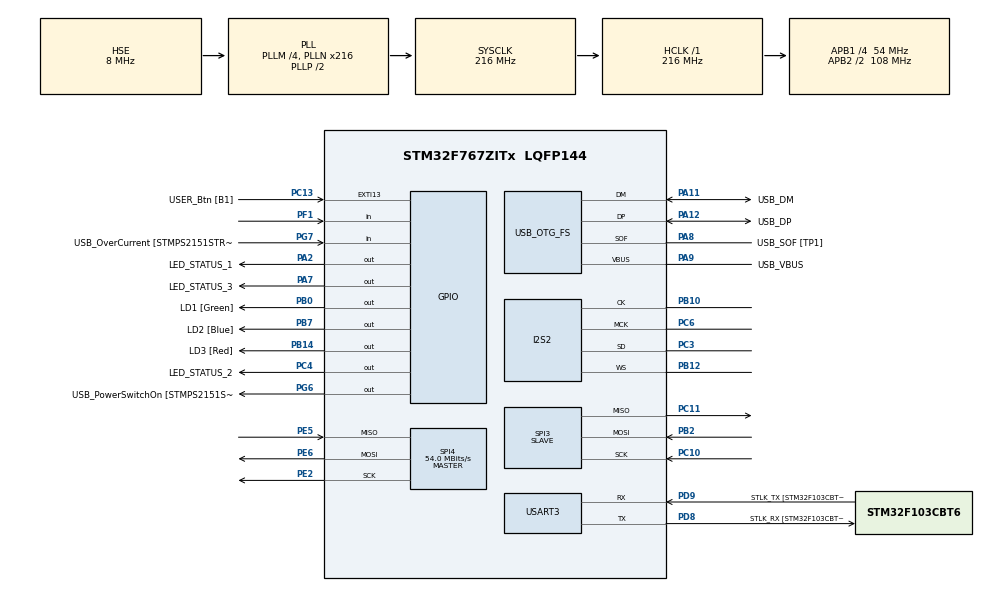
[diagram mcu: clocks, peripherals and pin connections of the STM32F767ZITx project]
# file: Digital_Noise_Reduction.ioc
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Dma.Request0=SPI2_RX
Dma.SPI2_RX.0.Direction=DMA_PERIPH_TO_MEMORY
Dma.SPI2_RX.0.FIFOMode=DMA_FIFOMODE_DISABLE
Dma.SPI2_RX.0.Instance=DMA1_Stream1
Dma.SPI2_RX.0.MemDataAlignment=DMA_MDATAALIGN_HALFWORD
Dma.SPI2_RX.0.MemInc=DMA_MINC_ENABLE
Dma.SPI2_RX.0.Mode=DMA_CIRCULAR
Dma.SPI2_RX.0.PeriphDataAlignment=DMA_PDATAALIGN_HALFWORD
Dma.SPI2_RX.0.PeriphInc=DMA_PINC_DISABLE
Dma.SPI2_RX.0.Priority=DMA_PRIORITY_HIGH
I2S2.AudioFreq=I2S_AUDIOFREQ_22K
I2S2.DataFormat=I2S_DATAFORMAT_24B
I2S2.ErrorAudioFreq=-0.06 %
I2S2.FullDuplexMode=I2S_FULLDUPLEXMODE_DISABLE
I2S2.Instance=SPI$Index
I2S2.Mode=I2S_MODE_MASTER_RX
I2S2.RealAudioFreq=21.986 KHz
I2S2.VirtualMode=I2S_MODE_MASTER
Mcu.Family=STM32F7
Mcu.Name=STM32F767ZITx
Mcu.Package=LQFP144
NVIC.DMA1_Stream1_IRQn=true\:0\:0\:false\:false\:true\:false\:true\:true
NVIC.OTG_FS_IRQn=true\:0\:0\:false\:false\:true\:false\:true\:true
NVIC.PriorityGroup=NVIC_PRIORITYGROUP_4
PA1.GPIO_Label=RMII_REF_CLK [LAN8742A-CZ-TR_REFCLK0]
PA1.Signal=ETH_REF_CLK
PA10.GPIO_Label=USB_ID
PA10.Signal=USB_OTG_FS_ID
PA11.GPIO_Label=USB_DM
PA11.Mode=Device_Only
PA11.Signal=USB_OTG_FS_DM
PA12.GPIO_Label=USB_DP
PA12.Mode=Device_Only
PA12.Signal=USB_OTG_FS_DP
PA13.GPIO_Label=TMS
PA13.Mode=Serial_Wire
PA13.Signal=SYS_JTMS-SWDIO
PA14.GPIO_Label=TCK
PA14.Mode=Serial_Wire
PA14.Signal=SYS_JTCK-SWCLK
PA2.GPIO_Label=LED_STATUS_1
PA2.Signal=GPIO_Output
PA7.GPIO_Label=LED_STATUS_3
PA7.Signal=GPIO_Output
PA8.GPIO_Label=USB_SOF [TP1]
PA8.Mode=Activate_SOF_FS
PA8.Signal=USB_OTG_FS_SOF
PA9.GPIO_Label=USB_VBUS
PA9.Mode=Activate_VBUS
PA9.Signal=USB_OTG_FS_VBUS
PB0.GPIO_Label=LD1 [Green]
PB0.Signal=GPIO_Output
PB10.Mode=Half_Duplex_Master
PB10.Signal=I2S2_CK
PB12.Mode=Half_Duplex_Master
PB12.Signal=I2S2_WS
PB13.GPIO_Label=RMII_TXD1 [LAN8742A-CZ-TR_TXD1]
PB13.Signal=ETH_TXD1
PB14.GPIO_Label=LD3 [Red]
PB14.Signal=GPIO_Output
PB2.Mode=Full_Duplex_Slave
PB2.Signal=SPI3_MOSI
PB3.GPIO_Label=SWO
PB3.Signal=SYS_JTDO-SWO
PB7.GPIO_Label=LD2 [Blue]
PB7.Signal=GPIO_Output
PC1.GPIO_Label=RMII_MDC [LAN8742A-CZ-TR_MDC]
PC1.Signal=ETH_MDC
PC10.Mode=Full_Duplex_Slave
PC10.Signal=SPI3_SCK
PC11.Mode=Full_Duplex_Slave
PC11.Signal=SPI3_MISO
PC13.GPIO_Label=USER_Btn [B1]
PC13.Signal=GPXTI13
PC14/OSC32_IN.Mode=LSE-External-Oscillator
PC14/OSC32_IN.Signal=RCC_OSC32_IN
PC15/OSC32_OUT.Mode=LSE-External-Oscillator
PC15/OSC32_OUT.Signal=RCC_OSC32_OUT
PC3.Mode=Half_Duplex_Master
PC3.Signal=I2S2_SD
PC4.GPIO_Label=LED_STATUS_2
PC4.Signal=GPIO_Output
PC5.GPIO_Label=RMII_RXD1 [LAN8742A-CZ-TR_RXD1]
PC5.Signal=ETH_RXD1
PC6.Mode=Master_Clock_Activated
PC6.Signal=I2S2_MCK
PD8.GPIO_Label=STLK_RX [STM32F103CBT6_PA3]
PD8.Mode=Asynchronous
PD8.Signal=USART3_TX
PD9.GPIO_Label=STLK_TX [STM32F103CBT6_PA2]
PD9.Mode=Asynchronous
PD9.Signal=USART3_RX
PE2.Mode=Full_Duplex_Master
PE2.Signal=SPI4_SCK
PE5.Mode=Full_Duplex_Master
PE5.Signal=SPI4_MISO
PE6.Mode=Full_Duplex_Master
PE6.Signal=SPI4_MOSI
PF1.Signal=GPIO_Input
PG11.GPIO_Label=RMII_TX_EN [LAN8742A-CZ-TR_TXEN]
PG11.Signal=ETH_TX_EN
PG13.GPIO_Label=RMII_TXD0 [LAN8742A-CZ-TR_TXD0]
PG13.Signal=ETH_TXD0
PG6.GPIO_Label=USB_PowerSwitchOn [STMPS2151STR_EN]
PG6.Signal=GPIO_Output
PG7.GPIO_Label=USB_OverCurrent [STMPS2151STR_FAULT]
PG7.Signal=GPIO_Input
PH0/OSC_IN.GPIO_Label=MCO [STM32F103CBT6_PA8]
PH0/OSC_IN.Mode=HSE-External-Clock-Source
PH0/OSC_IN.Signal=RCC_OSC_IN
PH1/OSC_OUT.Mode=HSE-External-Clock-Source
PH1/OSC_OUT.Signal=RCC_OSC_OUT
ProjectManager.HeapSize=0x200
ProjectManager.StackSize=0x400
ProjectManager.TargetToolchain=STM32CubeIDE
RCC.48MHZClocksFreq_Value=24000000
RCC.AHBFreq_Value=216000000
RCC.APB1CLKDivider=RCC_HCLK_DIV4
RCC.APB1Freq_Value=54000000
RCC.APB1TimFreq_Value=108000000
RCC.APB2CLKDivider=RCC_HCLK_DIV2
RCC.APB2Freq_Value=108000000
RCC.APB2TimFreq_Value=216000000
RCC.CortexFreq_Value=216000000
RCC.HCLKFreq_Value=216000000
RCC.HSE_VALUE=8000000
RCC.HSI_VALUE=16000000
RCC.PLLI2SN=197
RCC.PLLM=4
RCC.PLLMUL=RCC_PLL_MUL9
RCC.PLLN=216
RCC.PLLQ=9
RCC.PRESCALERUSB=RCC_USBCLKSOURCE_PLL_DIV1_5
RCC.SYSCLKFreq_VALUE=216000000
RCC.SYSCLKSource=RCC_SYSCLKSOURCE_PLLCLK
RCC.SYSCLKSourceVirtual=RCC_SYSCLKSOURCE_PLLCLK
RCC.USBFreq_Value=48000000
RCC.VCOOutputFreq_Value=432000000
SPI3.Direction=SPI_DIRECTION_2LINES
SPI3.Mode=SPI_MODE_SLAVE
SPI3.VirtualType=VM_SLAVE
SPI4.CalculateBaudRate=54.0 MBits/s
SPI4.Direction=SPI_DIRECTION_2LINES
SPI4.Mode=SPI_MODE_MASTER
SPI4.VirtualType=VM_MASTER
USART3.VirtualMode-Asynchronous=VM_ASYNC
USB_DEVICE.CLASS_NAME_FS=CDC
USB_DEVICE.VirtualMode-CDC_FS=Cdc
USB_DEVICE.VirtualModeFS=Cdc_FS
USB_OTG_FS.VirtualMode=Device_Only
VP_USB_DEVICE_VS_USB_DEVICE_CDC_FS.Mode=CDC_FS
board=NUCLEO-F767ZI

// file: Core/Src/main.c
/* USER CODE BEGIN Header */
/**
  ******************************************************************************
  * @file           : main.c
  * @brief          : Main program body
  ******************************************************************************
  * @attention
  *
  * Copyright (c) 2024 STMicroelectronics.
  * All rights reserved.
  *
  * This software is licensed under terms that can be found in the LICENSE file
  * in the root directory of this software component.
  * If no LICENSE file comes with this software, it is provided AS-IS.
  *
  ******************************************************************************
  */
/* USER CODE END Header */
#include "main.h"
#include "usb_device.h"

/* USER CODE BEGIN Includes */
#include "arm_math.h"
/* USER CODE END Includes */

I2S_HandleTypeDef hi2s2;
DMA_HandleTypeDef hdma_spi2_rx;

SPI_HandleTypeDef hspi3;
SPI_HandleTypeDef hspi4;

UART_HandleTypeDef huart3;

/* USER CODE BEGIN PV */

float32_t a[5] = {1,2,3,4,5};
float32_t b[5] = {1,2,3,4,5};
float32_t c[9];

/* USER CODE END PV */

void SystemClock_Config(void);
static void MX_GPIO_Init(void);
static void MX_DMA_Init(void);
static void MX_SPI3_Init(void);
static void MX_SPI4_Init(void);
static void MX_I2S2_Init(void);
static void MX_USART3_UART_Init(void);

int main(void)
{

  /* MCU Configuration--------------------------------------------------------*/

  /* Reset of all peripherals, Initializes the Flash interface and the Systick. */
  HAL_Init();

  /* Configure the system clock */
  SystemClock_Config();

  /* Initialize all configured peripherals */
  MX_GPIO_Init();
  MX_DMA_Init();
  MX_SPI3_Init();
  MX_SPI4_Init();
  MX_USB_DEVICE_Init();
  MX_I2S2_Init();
  MX_USART3_UART_Init();
  /* USER CODE BEGIN 2 */
  arm_conv_f32(a,5,b,5,c);
  /* USER CODE END 2 */

  /* Infinite loop */
  while (1)
  {

  }
}

void SystemClock_Config(void)
{
  RCC_OscInitTypeDef RCC_OscInitStruct = {0};
  RCC_ClkInitTypeDef RCC_ClkInitStruct = {0};

  /** Configure LSE Drive Capability
  */
  HAL_PWR_EnableBkUpAccess();

  /** Configure the main internal regulator output voltage
  */
  __HAL_RCC_PWR_CLK_ENABLE();
  __HAL_PWR_VOLTAGESCALING_CONFIG(PWR_REGULATOR_VOLTAGE_SCALE1);

  /** Initializes the RCC Oscillators according to the specified parameters
  * in the RCC_OscInitTypeDef structure.
  */
  RCC_OscInitStruct.OscillatorType = RCC_OSCILLATORTYPE_HSE;
  RCC_OscInitStruct.HSEState = RCC_HSE_BYPASS;
  RCC_OscInitStruct.PLL.PLLState = RCC_PLL_ON;
  RCC_OscInitStruct.PLL.PLLSource = RCC_PLLSOURCE_HSE;
  RCC_OscInitStruct.PLL.PLLM = 4;
  RCC_OscInitStruct.PLL.PLLN = 216;
  RCC_OscInitStruct.PLL.PLLP = RCC_PLLP_DIV2;
  RCC_OscInitStruct.PLL.PLLQ = 9;
  RCC_OscInitStruct.PLL.PLLR = 2;
  if (HAL_RCC_OscConfig(&RCC_OscInitStruct) != HAL_OK)
  {
    Error_Handler();
  }

  /** Activate the Over-Drive mode
  */
  if (HAL_PWREx_EnableOverDrive() != HAL_OK)
  {
    Error_Handler();
  }

  /** Initializes the CPU, AHB and APB buses clocks
  */
  RCC_ClkInitStruct.ClockType = RCC_CLOCKTYPE_HCLK|RCC_CLOCKTYPE_SYSCLK
                              |RCC_CLOCKTYPE_PCLK1|RCC_CLOCKTYPE_PCLK2;
  RCC_ClkInitStruct.SYSCLKSource = RCC_SYSCLKSOURCE_PLLCLK;
  RCC_ClkInitStruct.AHBCLKDivider = RCC_SYSCLK_DIV1;
  RCC_ClkInitStruct.APB1CLKDivider = RCC_HCLK_DIV4;
  RCC_ClkInitStruct.APB2CLKDivider = RCC_HCLK_DIV2;

  if (HAL_RCC_ClockConfig(&RCC_ClkInitStruct, FLASH_LATENCY_7) != HAL_OK)
  {
    Error_Handler();
  }
}

static void MX_I2S2_Init(void)
{

  hi2s2.Instance = SPI2;
  hi2s2.Init.Mode = I2S_MODE_MASTER_RX;
  hi2s2.Init.Standard = I2S_STANDARD_PHILIPS;
  hi2s2.Init.DataFormat = I2S_DATAFORMAT_24B;
  hi2s2.Init.MCLKOutput = I2S_MCLKOUTPUT_ENABLE;
  hi2s2.Init.AudioFreq = I2S_AUDIOFREQ_22K;
  hi2s2.Init.CPOL = I2S_CPOL_LOW;
  hi2s2.Init.ClockSource = I2S_CLOCK_PLL;
  if (HAL_I2S_Init(&hi2s2) != HAL_OK)
  {
    Error_Handler();
  }

}

static void MX_SPI3_Init(void)
{

  /* SPI3 parameter configuration*/
  hspi3.Instance = SPI3;
  hspi3.Init.Mode = SPI_MODE_SLAVE;
  hspi3.Init.Direction = SPI_DIRECTION_2LINES;
  hspi3.Init.DataSize = SPI_DATASIZE_4BIT;
  hspi3.Init.CLKPolarity = SPI_POLARITY_LOW;
  hspi3.Init.CLKPhase = SPI_PHASE_1EDGE;
  hspi3.Init.NSS = SPI_NSS_SOFT;
  hspi3.Init.FirstBit = SPI_FIRSTBIT_MSB;
  hspi3.Init.TIMode = SPI_TIMODE_DISABLE;
  hspi3.Init.CRCCalculation = SPI_CRCCALCULATION_DISABLE;
  hspi3.Init.CRCPolynomial = 7;
  hspi3.Init.CRCLength = SPI_CRC_LENGTH_DATASIZE;
  hspi3.Init.NSSPMode = SPI_NSS_PULSE_DISABLE;
  if (HAL_SPI_Init(&hspi3) != HAL_OK)
  {
    Error_Handler();
  }

}

static void MX_SPI4_Init(void)
{

  /* SPI4 parameter configuration*/
  hspi4.Instance = SPI4;
  hspi4.Init.Mode = SPI_MODE_MASTER;
  hspi4.Init.Direction = SPI_DIRECTION_2LINES;
  hspi4.Init.DataSize = SPI_DATASIZE_4BIT;
  hspi4.Init.CLKPolarity = SPI_POLARITY_LOW;
  hspi4.Init.CLKPhase = SPI_PHASE_1EDGE;
  hspi4.Init.NSS = SPI_NSS_SOFT;
  hspi4.Init.BaudRatePrescaler = SPI_BAUDRATEPRESCALER_2;
  hspi4.Init.FirstBit = SPI_FIRSTBIT_MSB;
  hspi4.Init.TIMode = SPI_TIMODE_DISABLE;
  hspi4.Init.CRCCalculation = SPI_CRCCALCULATION_DISABLE;
  hspi4.Init.CRCPolynomial = 7;
  hspi4.Init.CRCLength = SPI_CRC_LENGTH_DATASIZE;
  hspi4.Init.NSSPMode = SPI_NSS_PULSE_ENABLE;
  if (HAL_SPI_Init(&hspi4) != HAL_OK)
  {
    Error_Handler();
  }

}

static void MX_USART3_UART_Init(void)
{

  huart3.Instance = USART3;
  huart3.Init.BaudRate = 115200;
  huart3.Init.WordLength = UART_WORDLENGTH_8B;
  huart3.Init.StopBits = UART_STOPBITS_1;
  huart3.Init.Parity = UART_PARITY_NONE;
  huart3.Init.Mode = UART_MODE_TX_RX;
  huart3.Init.HwFlowCtl = UART_HWCONTROL_NONE;
  huart3.Init.OverSampling = UART_OVERSAMPLING_16;
  huart3.Init.OneBitSampling = UART_ONE_BIT_SAMPLE_DISABLE;
  huart3.AdvancedInit.AdvFeatureInit = UART_ADVFEATURE_NO_INIT;
  if (HAL_UART_Init(&huart3) != HAL_OK)
  {
    Error_Handler();
  }

}

static void MX_DMA_Init(void)
{

  /* DMA controller clock enable */
  __HAL_RCC_DMA1_CLK_ENABLE();

  /* DMA interrupt init */
  /* DMA1_Stream1_IRQn interrupt configuration */
  HAL_NVIC_SetPriority(DMA1_Stream1_IRQn, 0, 0);
  HAL_NVIC_EnableIRQ(DMA1_Stream1_IRQn);

}

static void MX_GPIO_Init(void)
{
  GPIO_InitTypeDef GPIO_InitStruct = {0};

  /* GPIO Ports Clock Enable */
  __HAL_RCC_GPIOE_CLK_ENABLE();
  __HAL_RCC_GPIOC_CLK_ENABLE();
  __HAL_RCC_GPIOF_CLK_ENABLE();
  __HAL_RCC_GPIOH_CLK_ENABLE();
  __HAL_RCC_GPIOA_CLK_ENABLE();
  __HAL_RCC_GPIOB_CLK_ENABLE();
  __HAL_RCC_GPIOD_CLK_ENABLE();
  __HAL_RCC_GPIOG_CLK_ENABLE();

  /*Configure GPIO pin Output Level */
  HAL_GPIO_WritePin(GPIOA, LED_STATUS_1_Pin|LED_STATUS_3_Pin, GPIO_PIN_RESET);

  /*Configure GPIO pin Output Level */
  HAL_GPIO_WritePin(LED_STATUS_2_GPIO_Port, LED_STATUS_2_Pin, GPIO_PIN_RESET);

  /*Configure GPIO pin Output Level */
  HAL_GPIO_WritePin(GPIOB, LD1_Pin|LD3_Pin|LD2_Pin, GPIO_PIN_RESET);

  /*Configure GPIO pin Output Level */
  HAL_GPIO_WritePin(USB_PowerSwitchOn_GPIO_Port, USB_PowerSwitchOn_Pin, GPIO_PIN_RESET);

  /*Configure GPIO pin : USER_Btn_Pin */
  GPIO_InitStruct.Pin = USER_Btn_Pin;
  GPIO_InitStruct.Mode = GPIO_MODE_IT_RISING;
  GPIO_InitStruct.Pull = GPIO_NOPULL;
  HAL_GPIO_Init(USER_Btn_GPIO_Port, &GPIO_InitStruct);

  /*Configure GPIO pin : PF1 */
  GPIO_InitStruct.Pin = GPIO_PIN_1;
  GPIO_InitStruct.Mode = GPIO_MODE_INPUT;
  GPIO_InitStruct.Pull = GPIO_NOPULL;
  HAL_GPIO_Init(GPIOF, &GPIO_InitStruct);

  /*Configure GPIO pins : RMII_MDC_Pin RMII_RXD1_Pin */
  GPIO_InitStruct.Pin = RMII_MDC_Pin|RMII_RXD1_Pin;
  GPIO_InitStruct.Mode = GPIO_MODE_AF_PP;
  GPIO_InitStruct.Pull = GPIO_NOPULL;
  GPIO_InitStruct.Speed = GPIO_SPEED_FREQ_VERY_HIGH;
  GPIO_InitStruct.Alternate = GPIO_AF11_ETH;
  HAL_GPIO_Init(GPIOC, &GPIO_InitStruct);

  /*Configure GPIO pin : RMII_REF_CLK_Pin */
  GPIO_InitStruct.Pin = RMII_REF_CLK_Pin;
  GPIO_InitStruct.Mode = GPIO_MODE_AF_PP;
  GPIO_InitStruct.Pull = GPIO_NOPULL;
  GPIO_InitStruct.Speed = GPIO_SPEED_FREQ_VERY_HIGH;
  GPIO_InitStruct.Alternate = GPIO_AF11_ETH;
  HAL_GPIO_Init(RMII_REF_CLK_GPIO_Port, &GPIO_InitStruct);

  /*Configure GPIO pins : LED_STATUS_1_Pin LED_STATUS_3_Pin */
  GPIO_InitStruct.Pin = LED_STATUS_1_Pin|LED_STATUS_3_Pin;
  GPIO_InitStruct.Mode = GPIO_MODE_OUTPUT_PP;
  GPIO_InitStruct.Pull = GPIO_NOPULL;
  GPIO_InitStruct.Speed = GPIO_SPEED_FREQ_LOW;
  HAL_GPIO_Init(GPIOA, &GPIO_InitStruct);

  /*Configure GPIO pin : LED_STATUS_2_Pin */
  GPIO_InitStruct.Pin = LED_STATUS_2_Pin;
  GPIO_InitStruct.Mode = GPIO_MODE_OUTPUT_PP;
  GPIO_InitStruct.Pull = GPIO_NOPULL;
  GPIO_InitStruct.Speed = GPIO_SPEED_FREQ_LOW;
  HAL_GPIO_Init(LED_STATUS_2_GPIO_Port, &GPIO_InitStruct);

  /*Configure GPIO pins : LD1_Pin LD3_Pin LD2_Pin */
  GPIO_InitStruct.Pin = LD1_Pin|LD3_Pin|LD2_Pin;
  GPIO_InitStruct.Mode = GPIO_MODE_OUTPUT_PP;
  GPIO_InitStruct.Pull = GPIO_NOPULL;
  GPIO_InitStruct.Speed = GPIO_SPEED_FREQ_LOW;
  HAL_GPIO_Init(GPIOB, &GPIO_InitStruct);

  /*Configure GPIO pin : RMII_TXD1_Pin */
  GPIO_InitStruct.Pin = RMII_TXD1_Pin;
  GPIO_InitStruct.Mode = GPIO_MODE_AF_PP;
  GPIO_InitStruct.Pull = GPIO_NOPULL;
  GPIO_InitStruct.Speed = GPIO_SPEED_FREQ_VERY_HIGH;
  GPIO_InitStruct.Alternate = GPIO_AF11_ETH;
  HAL_GPIO_Init(RMII_TXD1_GPIO_Port, &GPIO_InitStruct);

  /*Configure GPIO pin : USB_PowerSwitchOn_Pin */
  GPIO_InitStruct.Pin = USB_PowerSwitchOn_Pin;
  GPIO_InitStruct.Mode = GPIO_MODE_OUTPUT_PP;
  GPIO_InitStruct.Pull = GPIO_NOPULL;
  GPIO_InitStruct.Speed = GPIO_SPEED_FREQ_LOW;
  HAL_GPIO_Init(USB_PowerSwitchOn_GPIO_Port, &GPIO_InitStruct);

  /*Configure GPIO pin : USB_OverCurrent_Pin */
  GPIO_InitStruct.Pin = USB_OverCurrent_Pin;
  GPIO_InitStruct.Mode = GPIO_MODE_INPUT;
  GPIO_InitStruct.Pull = GPIO_NOPULL;
  HAL_GPIO_Init(USB_OverCurrent_GPIO_Port, &GPIO_InitStruct);

  /*Configure GPIO pins : RMII_TX_EN_Pin RMII_TXD0_Pin */
  GPIO_InitStruct.Pin = RMII_TX_EN_Pin|RMII_TXD0_Pin;
  GPIO_InitStruct.Mode = GPIO_MODE_AF_PP;
  GPIO_InitStruct.Pull = GPIO_NOPULL;
  GPIO_InitStruct.Speed = GPIO_SPEED_FREQ_VERY_HIGH;
  GPIO_InitStruct.Alternate = GPIO_AF11_ETH;
  HAL_GPIO_Init(GPIOG, &GPIO_InitStruct);

}

void Error_Handler(void)
{
  __disable_irq();
  while (1)
  {
  }
}
